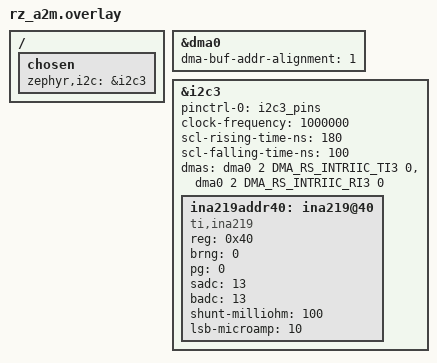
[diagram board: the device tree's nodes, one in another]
/ {
	chosen {
		zephyr,i2c = &i2c3;
	};
};

&dma0 {
	status = "okay";
	dma-buf-addr-alignment = <1>;
};

&i2c3 {
	pinctrl-0 = <&i2c3_pins>;
	pinctrl-names = "default";
	status = "okay";
	clock-frequency = <1000000>;
	scl-rising-time-ns = <180>;
	scl-falling-time-ns = <100>;
	dmas = <&dma0 2 DMA_RS_INTRIIC_TI3 0>, <&dma0 2 DMA_RS_INTRIIC_RI3 0>;
	dma-names = "tx", "rx";

	ina219addr40: ina219@40 {
		status = "okay";
		compatible = "ti,ina219";
		reg = <0x40>;
		brng = <0>;
		pg = <0>;
		sadc = <13>;
		badc = <13>;
		shunt-milliohm = <100>;
		lsb-microamp = <10>;
	};
};
